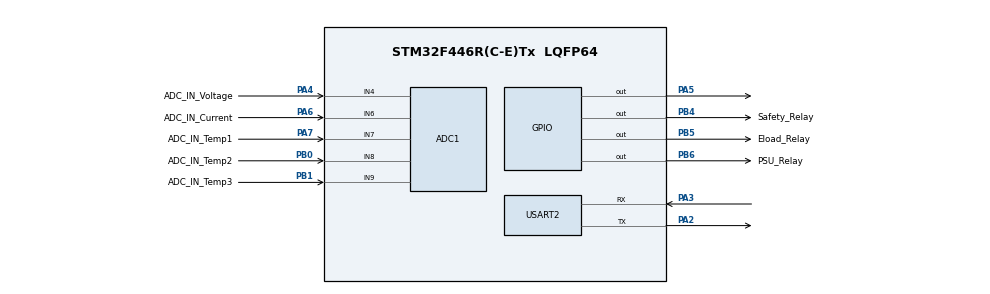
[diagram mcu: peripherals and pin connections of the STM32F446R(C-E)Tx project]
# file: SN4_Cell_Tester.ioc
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ADC1.Channel-1\#ChannelRegularConversion=ADC_CHANNEL_4
ADC1.Channel-2\#ChannelRegularConversion=ADC_CHANNEL_6
ADC1.Channel-3\#ChannelRegularConversion=ADC_CHANNEL_7
ADC1.Channel-4\#ChannelRegularConversion=ADC_CHANNEL_8
ADC1.Channel-5\#ChannelRegularConversion=ADC_CHANNEL_9
ADC1.ContinuousConvMode=ENABLE
ADC1.NbrOfConversion=5
ADC1.NbrOfConversionFlag=1
ADC1.Rank-1\#ChannelRegularConversion=1
ADC1.Rank-2\#ChannelRegularConversion=2
ADC1.Rank-3\#ChannelRegularConversion=3
ADC1.Rank-4\#ChannelRegularConversion=4
ADC1.Rank-5\#ChannelRegularConversion=5
ADC1.SamplingTime-1\#ChannelRegularConversion=ADC_SAMPLETIME_3CYCLES
ADC1.SamplingTime-2\#ChannelRegularConversion=ADC_SAMPLETIME_3CYCLES
ADC1.SamplingTime-3\#ChannelRegularConversion=ADC_SAMPLETIME_3CYCLES
ADC1.SamplingTime-4\#ChannelRegularConversion=ADC_SAMPLETIME_3CYCLES
ADC1.SamplingTime-5\#ChannelRegularConversion=ADC_SAMPLETIME_3CYCLES
ADC1.ScanConvMode=ENABLE
ADC1.master=1
Mcu.Family=STM32F4
Mcu.Name=STM32F446R(C-E)Tx
Mcu.Package=LQFP64
NVIC.PriorityGroup=NVIC_PRIORITYGROUP_4
NVIC.TIM8_UP_TIM13_IRQn=true\:0\:0\:false\:false\:true\:true\:true\:true
PA2.Mode=Asynchronous
PA2.Signal=USART2_TX
PA3.Mode=Asynchronous
PA3.Signal=USART2_RX
PA4.GPIO_Label=ADC_IN_Voltage
PA4.Signal=ADCx_IN4
PA5.Signal=GPIO_Output
PA6.GPIO_Label=ADC_IN_Current
PA6.Signal=ADCx_IN6
PA7.GPIO_Label=ADC_IN_Temp1
PA7.Signal=ADCx_IN7
PB0.GPIO_Label=ADC_IN_Temp2
PB0.Signal=ADCx_IN8
PB1.GPIO_Label=ADC_IN_Temp3
PB1.Signal=ADCx_IN9
PB4.GPIO_Label=Safety_Relay
PB4.Signal=GPIO_Output
PB5.GPIO_Label=Eload_Relay
PB5.Signal=GPIO_Output
PB6.GPIO_Label=PSU_Relay
PB6.Signal=GPIO_Output
ProjectManager.HeapSize=0x200
ProjectManager.StackSize=0x400
ProjectManager.TargetToolchain=STM32CubeIDE
RCC.APB2Freq_Value=16000000
RCC.APB2TimFreq_Value=16000000
RCC.CortexFreq_Value=16000000
RCC.USBFreq_Value=96000000
RCC.VCOOutputFreq_Value=192000000
SH.ADCx_IN4.0=ADC1_IN4,IN4
SH.ADCx_IN6.0=ADC1_IN6,IN6
SH.ADCx_IN7.0=ADC1_IN7,IN7
SH.ADCx_IN8.0=ADC1_IN8,IN8
SH.ADCx_IN9.0=ADC1_IN9,IN9
TIM13.Period=10000
TIM13.Prescaler=15
USART2.VirtualMode=VM_ASYNC
VP_TIM13_VS_ClockSourceINT.Mode=Enable_Timer
board=custom

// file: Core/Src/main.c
/* USER CODE BEGIN Header */
/**
  ******************************************************************************
  * @file           : main.c
  * @brief          : Main program body
  ******************************************************************************
  * @attention
  *
  * Copyright (c) 2024 STMicroelectronics.
  * All rights reserved.
  *
  * This software is licensed under terms that can be found in the LICENSE file
  * in the root directory of this software component.
  * If no LICENSE file comes with this software, it is provided AS-IS.
  *
  ******************************************************************************
  */
/* USER CODE END Header */
#include "main.h"

ADC_HandleTypeDef hadc1;

TIM_HandleTypeDef htim13;

UART_HandleTypeDef huart2;

void SystemClock_Config(void);
static void MX_GPIO_Init(void);
static void MX_USART2_UART_Init(void);
static void MX_ADC1_Init(void);
static void MX_TIM13_Init(void);

int main(void)
{

  /* MCU Configuration--------------------------------------------------------*/

  /* Reset of all peripherals, Initializes the Flash interface and the Systick. */
  HAL_Init();

  /* Configure the system clock */
  SystemClock_Config();

  /* Initialize all configured peripherals */
  MX_GPIO_Init();
  MX_USART2_UART_Init();
  MX_ADC1_Init();
  MX_TIM13_Init();
  /* USER CODE BEGIN 2 */

  FEB_Main_Setup();
  //HAL_TIM_Base_Start(&htim13);

  /* USER CODE END 2 */

  /* Infinite loop */
  while (1)
  {

    /* USER CODE BEGIN 3 */

	  FEB_Main_Loop();
  }
  /* USER CODE END 3 */
}

void SystemClock_Config(void)
{
  RCC_OscInitTypeDef RCC_OscInitStruct = {0};
  RCC_ClkInitTypeDef RCC_ClkInitStruct = {0};

  /** Configure the main internal regulator output voltage
  */
  __HAL_RCC_PWR_CLK_ENABLE();
  __HAL_PWR_VOLTAGESCALING_CONFIG(PWR_REGULATOR_VOLTAGE_SCALE3);

  /** Initializes the RCC Oscillators according to the specified parameters
  * in the RCC_OscInitTypeDef structure.
  */
  RCC_OscInitStruct.OscillatorType = RCC_OSCILLATORTYPE_HSI;
  RCC_OscInitStruct.HSIState = RCC_HSI_ON;
  RCC_OscInitStruct.HSICalibrationValue = RCC_HSICALIBRATION_DEFAULT;
  RCC_OscInitStruct.PLL.PLLState = RCC_PLL_NONE;
  if (HAL_RCC_OscConfig(&RCC_OscInitStruct) != HAL_OK)
  {
    Error_Handler();
  }

  /** Initializes the CPU, AHB and APB buses clocks
  */
  RCC_ClkInitStruct.ClockType = RCC_CLOCKTYPE_HCLK|RCC_CLOCKTYPE_SYSCLK
                              |RCC_CLOCKTYPE_PCLK1|RCC_CLOCKTYPE_PCLK2;
  RCC_ClkInitStruct.SYSCLKSource = RCC_SYSCLKSOURCE_HSI;
  RCC_ClkInitStruct.AHBCLKDivider = RCC_SYSCLK_DIV1;
  RCC_ClkInitStruct.APB1CLKDivider = RCC_HCLK_DIV1;
  RCC_ClkInitStruct.APB2CLKDivider = RCC_HCLK_DIV1;

  if (HAL_RCC_ClockConfig(&RCC_ClkInitStruct, FLASH_LATENCY_0) != HAL_OK)
  {
    Error_Handler();
  }
}

static void MX_ADC1_Init(void)
{

  ADC_ChannelConfTypeDef sConfig = {0};

  /** Configure the global features of the ADC (Clock, Resolution, Data Alignment and number of conversion)
  */
  hadc1.Instance = ADC1;
  hadc1.Init.ClockPrescaler = ADC_CLOCK_SYNC_PCLK_DIV2;
  hadc1.Init.Resolution = ADC_RESOLUTION_12B;
  hadc1.Init.ScanConvMode = ENABLE;
  hadc1.Init.ContinuousConvMode = ENABLE;
  hadc1.Init.DiscontinuousConvMode = DISABLE;
  hadc1.Init.ExternalTrigConvEdge = ADC_EXTERNALTRIGCONVEDGE_NONE;
  hadc1.Init.ExternalTrigConv = ADC_SOFTWARE_START;
  hadc1.Init.DataAlign = ADC_DATAALIGN_RIGHT;
  hadc1.Init.NbrOfConversion = 5;
  hadc1.Init.DMAContinuousRequests = DISABLE;
  hadc1.Init.EOCSelection = ADC_EOC_SINGLE_CONV;
  if (HAL_ADC_Init(&hadc1) != HAL_OK)
  {
    Error_Handler();
  }

  /** Configure for the selected ADC regular channel its corresponding rank in the sequencer and its sample time.
  */
  sConfig.Channel = ADC_CHANNEL_4;
  sConfig.Rank = 1;
  sConfig.SamplingTime = ADC_SAMPLETIME_3CYCLES;
  if (HAL_ADC_ConfigChannel(&hadc1, &sConfig) != HAL_OK)
  {
    Error_Handler();
  }

  /** Configure for the selected ADC regular channel its corresponding rank in the sequencer and its sample time.
  */
  sConfig.Channel = ADC_CHANNEL_6;
  sConfig.Rank = 2;
  if (HAL_ADC_ConfigChannel(&hadc1, &sConfig) != HAL_OK)
  {
    Error_Handler();
  }

  /** Configure for the selected ADC regular channel its corresponding rank in the sequencer and its sample time.
  */
  sConfig.Channel = ADC_CHANNEL_7;
  sConfig.Rank = 3;
  if (HAL_ADC_ConfigChannel(&hadc1, &sConfig) != HAL_OK)
  {
    Error_Handler();
  }

  /** Configure for the selected ADC regular channel its corresponding rank in the sequencer and its sample time.
  */
  sConfig.Channel = ADC_CHANNEL_8;
  sConfig.Rank = 4;
  if (HAL_ADC_ConfigChannel(&hadc1, &sConfig) != HAL_OK)
  {
    Error_Handler();
  }

  /** Configure for the selected ADC regular channel its corresponding rank in the sequencer and its sample time.
  */
  sConfig.Channel = ADC_CHANNEL_9;
  sConfig.Rank = 5;
  if (HAL_ADC_ConfigChannel(&hadc1, &sConfig) != HAL_OK)
  {
    Error_Handler();
  }

}

static void MX_TIM13_Init(void)
{

  htim13.Instance = TIM13;
  htim13.Init.Prescaler = 15;
  htim13.Init.CounterMode = TIM_COUNTERMODE_UP;
  htim13.Init.Period = 10000;
  htim13.Init.ClockDivision = TIM_CLOCKDIVISION_DIV1;
  htim13.Init.AutoReloadPreload = TIM_AUTORELOAD_PRELOAD_DISABLE;
  if (HAL_TIM_Base_Init(&htim13) != HAL_OK)
  {
    Error_Handler();
  }

}

static void MX_USART2_UART_Init(void)
{

  huart2.Instance = USART2;
  huart2.Init.BaudRate = 115200;
  huart2.Init.WordLength = UART_WORDLENGTH_8B;
  huart2.Init.StopBits = UART_STOPBITS_1;
  huart2.Init.Parity = UART_PARITY_NONE;
  huart2.Init.Mode = UART_MODE_TX_RX;
  huart2.Init.HwFlowCtl = UART_HWCONTROL_NONE;
  huart2.Init.OverSampling = UART_OVERSAMPLING_16;
  if (HAL_UART_Init(&huart2) != HAL_OK)
  {
    Error_Handler();
  }

}

static void MX_GPIO_Init(void)
{
  GPIO_InitTypeDef GPIO_InitStruct = {0};

  /* GPIO Ports Clock Enable */
  __HAL_RCC_GPIOA_CLK_ENABLE();
  __HAL_RCC_GPIOB_CLK_ENABLE();

  /*Configure GPIO pin Output Level */
  HAL_GPIO_WritePin(GPIOA, GPIO_PIN_5, GPIO_PIN_RESET);

  /*Configure GPIO pin Output Level */
  HAL_GPIO_WritePin(GPIOB, Safety_Relay_Pin|Eload_Relay_Pin|PSU_Relay_Pin, GPIO_PIN_RESET);

  /*Configure GPIO pin : PA5 */
  GPIO_InitStruct.Pin = GPIO_PIN_5;
  GPIO_InitStruct.Mode = GPIO_MODE_OUTPUT_PP;
  GPIO_InitStruct.Pull = GPIO_NOPULL;
  GPIO_InitStruct.Speed = GPIO_SPEED_FREQ_LOW;
  HAL_GPIO_Init(GPIOA, &GPIO_InitStruct);

  /*Configure GPIO pins : Safety_Relay_Pin Eload_Relay_Pin PSU_Relay_Pin */
  GPIO_InitStruct.Pin = Safety_Relay_Pin|Eload_Relay_Pin|PSU_Relay_Pin;
  GPIO_InitStruct.Mode = GPIO_MODE_OUTPUT_PP;
  GPIO_InitStruct.Pull = GPIO_NOPULL;
  GPIO_InitStruct.Speed = GPIO_SPEED_FREQ_LOW;
  HAL_GPIO_Init(GPIOB, &GPIO_InitStruct);

}

void Error_Handler(void)
{
  __disable_irq();
  while (1)
  {
  }
}
